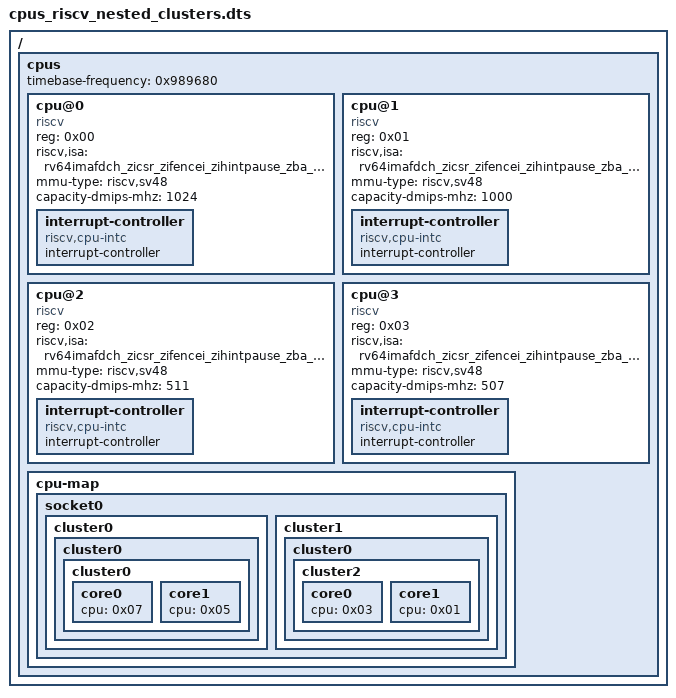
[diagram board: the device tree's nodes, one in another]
// Copyright 2023 The Fuchsia Authors. All rights reserved.
// Use of this source code is governed by a BSD-style license that can be
// found in the LICENSE file.

/dts-v1/;

/ {
    cpus {
        #address-cells = <0x01>;
        #size-cells = <0x00>;
        timebase-frequency = <0x989680>;

        cpu@0 {
            phandle = <0x07>;
            device_type = "cpu";
            reg = <0x00>;
            status = "okay";
            compatible = "riscv";
            riscv,isa = "rv64imafdch_zicsr_zifencei_zihintpause_zba_zbb_zbc_zbs_sstc";
            mmu-type = "riscv,sv48";
            capacity-dmips-mhz = <1024>;

            interrupt-controller {
                #address-cells = <0x01>;
                #interrupt-cells = <0x01>;
                interrupt-controller;
                compatible = "riscv,cpu-intc";
                phandle = <0x08>;
            };
        };

        cpu@1 {
            phandle = <0x05>;
            device_type = "cpu";
            reg = <0x01>;
            status = "okay";
            compatible = "riscv";
            riscv,isa = "rv64imafdch_zicsr_zifencei_zihintpause_zba_zbb_zbc_zbs_sstc";
            mmu-type = "riscv,sv48";
            capacity-dmips-mhz = <1000>;

            interrupt-controller {
                #address-cells = <0x01>;
                #interrupt-cells = <0x01>;
                interrupt-controller;
                compatible = "riscv,cpu-intc";
                phandle = <0x06>;
            };
        };

        cpu@2 {
            phandle = <0x03>;
            device_type = "cpu";
            reg = <0x02>;
            status = "okay";
            compatible = "riscv";
            riscv,isa = "rv64imafdch_zicsr_zifencei_zihintpause_zba_zbb_zbc_zbs_sstc";
            mmu-type = "riscv,sv48";
            capacity-dmips-mhz = <511>;

            interrupt-controller {
                #address-cells = <0x01>;
                #interrupt-cells = <0x01>;
                interrupt-controller;
                compatible = "riscv,cpu-intc";
                phandle = <0x04>;
            };
        };

        cpu@3 {
            phandle = <0x01>;
            device_type = "cpu";
            reg = <0x03>;
            status = "okay";
            compatible = "riscv";
            riscv,isa = "rv64imafdch_zicsr_zifencei_zihintpause_zba_zbb_zbc_zbs_sstc";
            mmu-type = "riscv,sv48";
            capacity-dmips-mhz = <507>;

            interrupt-controller {
                #address-cells = <0x01>;
                #interrupt-cells = <0x01>;
                interrupt-controller;
                compatible = "riscv,cpu-intc";
                phandle = <0x02>;
            };
        };

        cpu-map {
            socket0 {
                cluster0 {
                    cluster0 {
                        cluster0 {
                            core0 {
                                cpu = <0x07>;
                            };

                            core1 {
                                cpu = <0x05>;
                            };
                        };
                    };
                };
                cluster1 {
                    cluster0 {
                        cluster2 {
                            core0 {
                                cpu = <0x03>;
                            };

                            core1 {
                                cpu = <0x01>;
                            };
                        };
                    };
                };
            };
        };
    };
};
